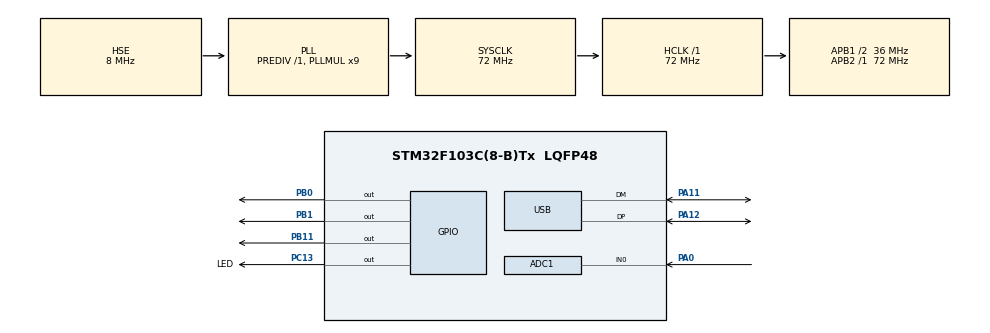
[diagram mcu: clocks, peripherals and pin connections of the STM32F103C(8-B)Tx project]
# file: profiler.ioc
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ADC1.Channel-2\#ChannelRegularConversion=ADC_CHANNEL_0
ADC1.ContinuousConvMode=DISABLE
ADC1.NbrOfConversionFlag=1
ADC1.Rank-2\#ChannelRegularConversion=1
ADC1.SamplingTime-2\#ChannelRegularConversion=ADC_SAMPLETIME_1CYCLE_5
ADC1.master=1
Mcu.Family=STM32F1
Mcu.Name=STM32F103C(8-B)Tx
Mcu.Package=LQFP48
NVIC.ADC1_2_IRQn=true\:0\:0\:false\:false\:true\:true
NVIC.PriorityGroup=NVIC_PRIORITYGROUP_4
NVIC.USB_LP_CAN1_RX0_IRQn=true\:0\:0\:false\:false\:true\:false
PA0-WKUP.Signal=ADCx_IN0
PA11.Mode=Device
PA11.Signal=USB_DM
PA12.Mode=Device
PA12.Signal=USB_DP
PA13.Mode=Serial_Wire
PA13.Signal=SYS_JTMS-SWDIO
PA14.Mode=Serial_Wire
PA14.Signal=SYS_JTCK-SWCLK
PB0.Signal=GPIO_Output
PB1.Signal=GPIO_Output
PB11.Signal=GPIO_Output
PC13-TAMPER-RTC.GPIO_Label=LED
PC13-TAMPER-RTC.Signal=GPIO_Output
PD0-OSC_IN.Mode=HSE-External-Oscillator
PD0-OSC_IN.Signal=RCC_OSC_IN
PD1-OSC_OUT.Mode=HSE-External-Oscillator
PD1-OSC_OUT.Signal=RCC_OSC_OUT
ProjectManager.HeapSize=0x200
ProjectManager.StackSize=0x400
ProjectManager.TargetToolchain=EWARM V7
RCC.ADCPresc=RCC_ADCPCLK2_DIV6
RCC.AHBFreq_Value=72000000
RCC.APB1CLKDivider=RCC_HCLK_DIV2
RCC.APB1Freq_Value=36000000
RCC.APB1TimFreq_Value=72000000
RCC.APB2Freq_Value=72000000
RCC.APB2TimFreq_Value=72000000
RCC.HCLKFreq_Value=72000000
RCC.PLLMUL=RCC_PLL_MUL9
RCC.SYSCLKFreq_VALUE=72000000
RCC.SYSCLKSource=RCC_SYSCLKSOURCE_PLLCLK
RCC.USBFreq_Value=48000000
RCC.USBPrescaler=RCC_USBCLKSOURCE_PLL_DIV1_5
SH.ADCx_IN0.0=ADC1_IN0,IN0
USB_DEVICE.CLASS_NAME_FS=CDC
USB_DEVICE.VirtualMode=Cdc
USB_DEVICE.VirtualModeFS=Cdc_FS
VP_USB_DEVICE_VS_USB_DEVICE_CDC_FS.Mode=CDC_FS
board=custom

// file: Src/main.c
//Firmware for LaserBeamProfiler
//Bluepill board - stm32f103c8t6

#include "main.h"
#include "stm32f1xx_hal.h"
#include "usb_device.h"

/* USER CODE BEGIN Includes */
#include "usbd_cdc_if.h"
#include "profiler.h"
/* USER CODE END Includes */

ADC_HandleTypeDef hadc1;

/* USER CODE BEGIN PV */
/* Private variables ---------------------------------------------------------*/

/* USER CODE END PV */

void SystemClock_Config(void);
static void MX_GPIO_Init(void);
static void MX_ADC1_Init(void);

/* USER CODE BEGIN PFP */
/* Private function prototypes -----------------------------------------------*/

/* USER CODE END PFP */

int main(void)
{

  /* MCU Configuration----------------------------------------------------------*/

  /* Reset of all peripherals, Initializes the Flash interface and the Systick. */
  HAL_Init();

  /* Configure the system clock */
  SystemClock_Config();

  /* USER CODE BEGIN SysInit */
  cdc_usb_reset();
  /* USER CODE END SysInit */

  /* Initialize all configured peripherals */
  MX_GPIO_Init();
  MX_USB_DEVICE_Init();
  MX_ADC1_Init();
  /* USER CODE BEGIN 2 */
  profiler_init();
  /* USER CODE END 2 */

  /* Infinite loop */
  while (1)
  {

  /* USER CODE BEGIN 3 */
  profiler_handler();
  }
  /* USER CODE END 3 */

}

void SystemClock_Config(void)
{

  RCC_OscInitTypeDef RCC_OscInitStruct;
  RCC_ClkInitTypeDef RCC_ClkInitStruct;
  RCC_PeriphCLKInitTypeDef PeriphClkInit;

    /**Initializes the CPU, AHB and APB busses clocks
    */
  RCC_OscInitStruct.OscillatorType = RCC_OSCILLATORTYPE_HSE;
  RCC_OscInitStruct.HSEState = RCC_HSE_ON;
  RCC_OscInitStruct.HSEPredivValue = RCC_HSE_PREDIV_DIV1;
  RCC_OscInitStruct.HSIState = RCC_HSI_ON;
  RCC_OscInitStruct.PLL.PLLState = RCC_PLL_ON;
  RCC_OscInitStruct.PLL.PLLSource = RCC_PLLSOURCE_HSE;
  RCC_OscInitStruct.PLL.PLLMUL = RCC_PLL_MUL9;
  if (HAL_RCC_OscConfig(&RCC_OscInitStruct) != HAL_OK)
  {
    _Error_Handler(__FILE__, __LINE__);
  }

    /**Initializes the CPU, AHB and APB busses clocks
    */
  RCC_ClkInitStruct.ClockType = RCC_CLOCKTYPE_HCLK|RCC_CLOCKTYPE_SYSCLK
                              |RCC_CLOCKTYPE_PCLK1|RCC_CLOCKTYPE_PCLK2;
  RCC_ClkInitStruct.SYSCLKSource = RCC_SYSCLKSOURCE_PLLCLK;
  RCC_ClkInitStruct.AHBCLKDivider = RCC_SYSCLK_DIV1;
  RCC_ClkInitStruct.APB1CLKDivider = RCC_HCLK_DIV2;
  RCC_ClkInitStruct.APB2CLKDivider = RCC_HCLK_DIV1;

  if (HAL_RCC_ClockConfig(&RCC_ClkInitStruct, FLASH_LATENCY_2) != HAL_OK)
  {
    _Error_Handler(__FILE__, __LINE__);
  }

  PeriphClkInit.PeriphClockSelection = RCC_PERIPHCLK_ADC|RCC_PERIPHCLK_USB;
  PeriphClkInit.AdcClockSelection = RCC_ADCPCLK2_DIV6;
  PeriphClkInit.UsbClockSelection = RCC_USBCLKSOURCE_PLL_DIV1_5;
  if (HAL_RCCEx_PeriphCLKConfig(&PeriphClkInit) != HAL_OK)
  {
    _Error_Handler(__FILE__, __LINE__);
  }

    /**Configure the Systick interrupt time
    */
  HAL_SYSTICK_Config(HAL_RCC_GetHCLKFreq()/1000);

    /**Configure the Systick
    */
  HAL_SYSTICK_CLKSourceConfig(SYSTICK_CLKSOURCE_HCLK);

  /* SysTick_IRQn interrupt configuration */
  HAL_NVIC_SetPriority(SysTick_IRQn, 0, 0);
}

/* ADC1 init function */
static void MX_ADC1_Init(void)
{

  ADC_ChannelConfTypeDef sConfig;

    /**Common config
    */
  hadc1.Instance = ADC1;
  hadc1.Init.ScanConvMode = ADC_SCAN_DISABLE;
  //hadc1.Init.ContinuousConvMode = ENABLE;
  hadc1.Init.ContinuousConvMode = DISABLE;
  hadc1.Init.DiscontinuousConvMode = DISABLE;
  hadc1.Init.ExternalTrigConv = ADC_SOFTWARE_START;
  hadc1.Init.DataAlign = ADC_DATAALIGN_RIGHT;
  hadc1.Init.NbrOfConversion = 1;
  if (HAL_ADC_Init(&hadc1) != HAL_OK)
  {
    _Error_Handler(__FILE__, __LINE__);
  }

    /**Configure Regular Channel
    */
  sConfig.Channel = ADC_CHANNEL_0;
  sConfig.Rank = ADC_REGULAR_RANK_1;
  sConfig.SamplingTime = ADC_SAMPLETIME_1CYCLE_5;
  if (HAL_ADC_ConfigChannel(&hadc1, &sConfig) != HAL_OK)
  {
    _Error_Handler(__FILE__, __LINE__);
  }

}

/** Configure pins as
        * Analog
        * Input
        * Output
        * EVENT_OUT
        * EXTI
*/
static void MX_GPIO_Init(void)
{

  GPIO_InitTypeDef GPIO_InitStruct;

  /* GPIO Ports Clock Enable */
  __HAL_RCC_GPIOC_CLK_ENABLE();
  __HAL_RCC_GPIOD_CLK_ENABLE();
  __HAL_RCC_GPIOA_CLK_ENABLE();
  __HAL_RCC_GPIOB_CLK_ENABLE();

  /*Configure GPIO pin Output Level */
  HAL_GPIO_WritePin(LED_GPIO_Port, LED_Pin, GPIO_PIN_RESET);

  /*Configure GPIO pin Output Level */
  HAL_GPIO_WritePin(GPIOB, GPIO_PIN_0|GPIO_PIN_1|GPIO_PIN_11, GPIO_PIN_RESET);

  /*Configure GPIO pin : LED_Pin */
  GPIO_InitStruct.Pin = LED_Pin;
  GPIO_InitStruct.Mode = GPIO_MODE_OUTPUT_PP;
  GPIO_InitStruct.Pull = GPIO_NOPULL;
  GPIO_InitStruct.Speed = GPIO_SPEED_FREQ_LOW;
  HAL_GPIO_Init(LED_GPIO_Port, &GPIO_InitStruct);

  /*Configure GPIO pins : PB0 PB1 PB11 */
  GPIO_InitStruct.Pin = GPIO_PIN_0|GPIO_PIN_1|GPIO_PIN_11;
  GPIO_InitStruct.Mode = GPIO_MODE_OUTPUT_PP;
  GPIO_InitStruct.Pull = GPIO_NOPULL;
  GPIO_InitStruct.Speed = GPIO_SPEED_FREQ_LOW;
  HAL_GPIO_Init(GPIOB, &GPIO_InitStruct);

}

void _Error_Handler(char *file, int line)
{
  while(1)
  {
  }
}

/************************ (C) COPYRIGHT STMicroelectronics *****END OF FILE****/
